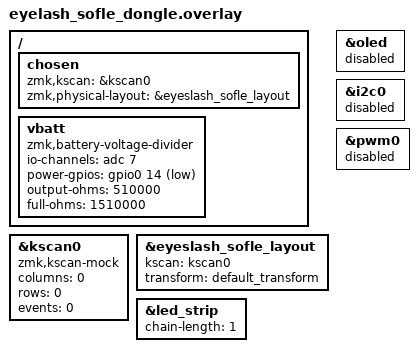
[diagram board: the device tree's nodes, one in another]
#include "eyelash_sofle.dtsi"

/ {
    chosen {
        zmk,kscan = &kscan0;
        zmk,physical-layout = &eyeslash_sofle_layout;
        /delete-property/ zmk,matrix-transform;
        /delete-property/ zephyr,display;
        /delete-property/ zmk,backlight;
    };

    /delete-node/ vbatt;

    vbatt: vbatt {
        compatible = "zmk,battery-voltage-divider";
        io-channels = <&adc 7>;
        power-gpios = <&gpio0 14 (GPIO_OPEN_DRAIN | GPIO_ACTIVE_LOW)>;
        output-ohms = <510000>;
        full-ohms = <1510000>;
    };
};

&kscan0 {
    compatible = "zmk,kscan-mock";
    /delete-property/ wakeup-source;
    /delete-property/ diode-direction;
    columns = <0>;
    rows = <0>;
    events = <0>;
};

&eyeslash_sofle_layout {
    kscan = <&kscan0>;
    transform = <&default_transform>;
};

&oled { status = "disabled"; };
&led_strip { chain-length = <1>; };
&i2c0 { status = "disabled"; };
&pwm0 { status = "disabled"; };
